# SIMG301M114KGH register map
Vendor: Silicon Labs; Series: Si; File version: B
Registers are 32-bit, read-write, reset 0x0 unless marked. A register's access mark holds for its fields unless they carry their own. Offsets are from the block's base; [hi:lo] are bit positions; {n}, {i} and the like mark numbered series; 'fields as' and 'values as' point back to an identical list.

## LFXO_NS — LFXO_NS Registers
Base 0x40820000
Same registers: LFXO_S 0x50820000
0x00 IPVERSION ro reset 0x2
  [31:0] IPVERSION — IP Version ID
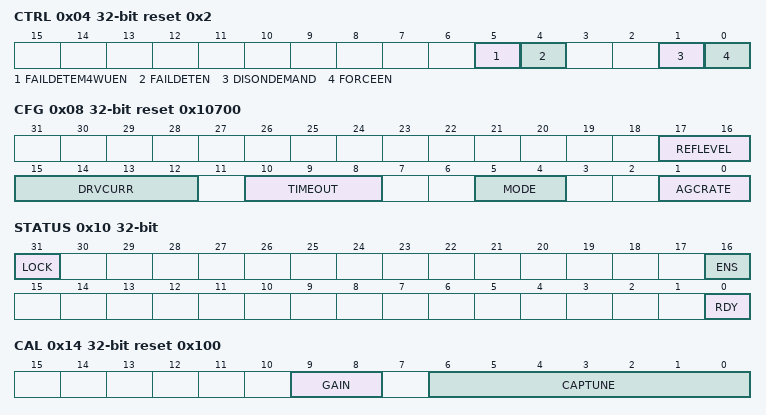
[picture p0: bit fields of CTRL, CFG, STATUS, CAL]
0x04 CTRL reset 0x2
  [5] FAILDETEM4WUEN — LFXO Failure Detection EM4WU Enable
  [4] FAILDETEN — LFXO Failure Detection Enable
  [1] DISONDEMAND — LFXO Disable On-demand requests
  [0] FORCEEN — LFXO Force Enable
0x08 CFG reset 0x10700 — Do not write to this register unless the oscillator is forced off. The oscillator is forced off if DISONDEMAND is set and FORCEEN is cleared.
  [17:16] REFLEVEL — LFXO Reference level for AGC
    0=MIN (low agc amplitude); 1=RESET (default); 3=MAX (high agc amplitude)
  [15:12] DRVCURR — LFXO Driver Current Setting
    0=AGC; {v}=FORCE_{v} (v=1..15)
  [10:8] TIMEOUT — LFXO Start-up Delay
    0=CYCLES2 (Timeout period of 2 cycles); 1=CYCLES256 (Timeout period of 256 cycles); 2=CYCLES1K (Timeout period of 1024 cycles); 3=CYCLES2K (Timeout period of 2048 cycles); 4=CYCLES4K (Timeout period of 4096 cycles); 5=CYCLES8K (Timeout period of 8192 cycles); 6=CYCLES16K (Timeout period of 16384 cycles); 7=CYCLES32K (Timeout period of 32768 cycles)
  [5:4] MODE — LFXO Mode
    0=XTAL (LFXO in Low Power mode. A 32768 Hz crystal should be connected to the LF crystal pads.); 1=XTAL_HP (LFXO in High Power mode. A 32768 Hz crystal should be connected to the LF crystal pads.); 2=BUFEXTCLK (An external sine source should be connected to LFXTAL_I pin. The input signal is internally AC coupled. Voltage should be kept above ground and below DVDD. LFXTAL_O pin is free to use as a GPIO.); 3=DIGEXTCLK (An external 32 kHz CMOS clock should be provided on LFXTAL_I. LFXTAL_O is free to be used as a general purpose GPIO.)
  [1:0] AGCRATE — LFXO AGC Refresh Rate
    0=SLOW (128k cycles); 1=MEDIUM (32k cycles); 2=FAST (8k cycles); 3=TEST (RESERVED)
0x10 STATUS ro
  [31] LOCK — LFXO Locked Status
    0=UNLOCKED (LFXO lockable registers are not locked); 1=LOCKED (LFXO lockable registers are locked)
  [16] ENS — LFXO Enable Status
  [0] RDY — LFXO Ready Status
0x14 CAL reset 0x100 — Do not write to this register unless CALBSY in SYNCBUSY register is low.
  [9:8] GAIN — LFXO Startup Gain
  [6:0] CAPTUNE — Internal Capacitance Tuning
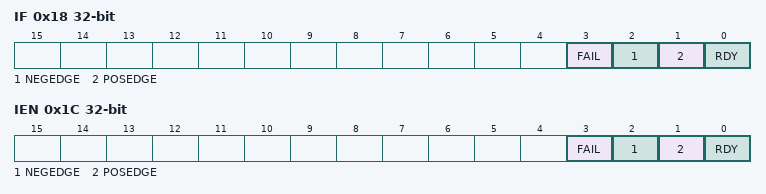
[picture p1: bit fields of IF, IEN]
0x18 IF
  [3] FAIL — LFXO Failure Interrupt Flag
  [2] NEGEDGE — Falling Edge Interrupt Flag
  [1] POSEDGE — Rising Edge Interrupt Flag
  [0] RDY — LFXO Ready Interrupt Flag
0x1C IEN
  [3] FAIL — LFXO Failure Interrupt Enable
  [2] NEGEDGE — Falling Edge Interrupt Enable
  [1] POSEDGE — Rising Edge Interrupt Enable
  [0] RDY — LFXO Ready Interrupt Enable
0x20 SYNCBUSY ro
  [0] CAL — LFXO Synchronization status
0x24 LOCK wo reset 0x1A20
  [15:0] LOCKKEY
    0x1A20=UNLOCK (Unlock LFXO lockable registers)
0x2C AGCCTRL
  [0] DISAGCCLK — LFXO AGC CLK Disable
    0=ENABLED (ENABLE AGC CLK); 1=DISABLED (DISABLE AGC CLK)

## PCNT0_NS — PCNT0_NS Registers
Base 0x40040000
Same registers: PCNT0_S 0x50040000
0x00 IPVERSION ro reset 0x1
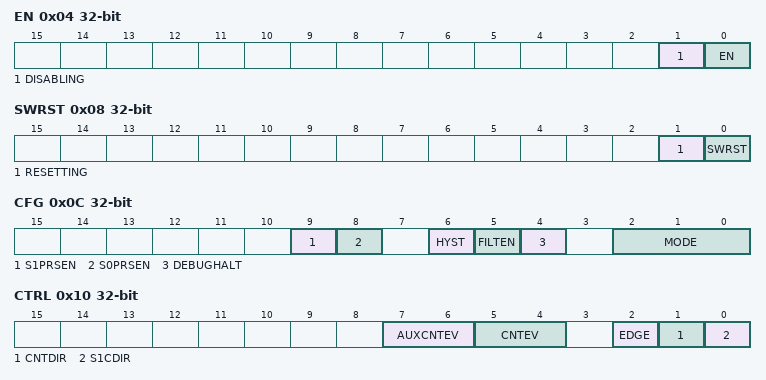
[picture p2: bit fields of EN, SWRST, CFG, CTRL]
0x04 EN
  [1] DISABLING ro — Disablement busy status
  [0] EN — PCNT Module Enable
0x08 SWRST
  [1] RESETTING ro — Software reset busy status
  [0] SWRST wo — Software reset command
0x0C CFG
  [9] S1PRSEN — S1IN PRS Enable
  [8] S0PRSEN — S0IN PRS Enable
  [6] HYST — Enable Hysteresis
  [5] FILTEN — Enable Digital Pulse Width Filter
  [4] DEBUGHALT — Debug Mode Halt Enable
    0=DISABLE (PCNT is running in debug mode.); 1=ENABLE (PCNT is frozen in debug mode.)
  [2:0] MODE — Mode Select
    0=OVSSINGLE (Single input EM23GRPACLK oversampling mode); 1=EXTCLKSINGLE (Externally clocked single input counter mode); 2=EXTCLKQUAD (Externally clocked quadrature decoder mode); 3=OVSQUAD1X (EM23GRPACLK oversampling quadrature decoder 1X mode); 4=OVSQUAD2X (EM23GRPACLK oversampling quadrature decoder 2X mode); 5=OVSQUAD4X (EM23GRPACLK oversampling quadrature decoder 4X mode)
0x10 CTRL
  [7:6] AUXCNTEV — Controls When the Aux Counter Counts
    0=BOTH (Counts up on both up-count and down-count events.); 1=UP (Counts up on up-count events.); 2=DOWN (Counts up on down-count events.)
  [5:4] CNTEV — Controls When the Counter Counts
    0=BOTH (Counts up on up-count and down on down-count events.); 1=UP (Only counts up on up-count events.); 2=DOWN (Only counts down on down-count events.)
  [2] EDGE — Edge Select
    0=POS (Positive edges on the PCNTn_S0IN inputs are counted in OVSSINGLE mode. Does not invert PCNTn_S1IN input in OVSSINGLE and EXTCLKSINGLE modes); 1=NEG (Negative edges on the PCNTn_S0IN inputs are counted in OVSSINGLE mode. Inverts the PCNTn_S1IN input in OVSSINGLE and EXTCLKSINGLE modes)
  [1] CNTDIR — Non-Quadrature Mode Counter Direction Co
    0=UP (Up counter mode.); 1=DOWN (Down counter mode.)
  [0] S1CDIR — Count Direction Determined By S1
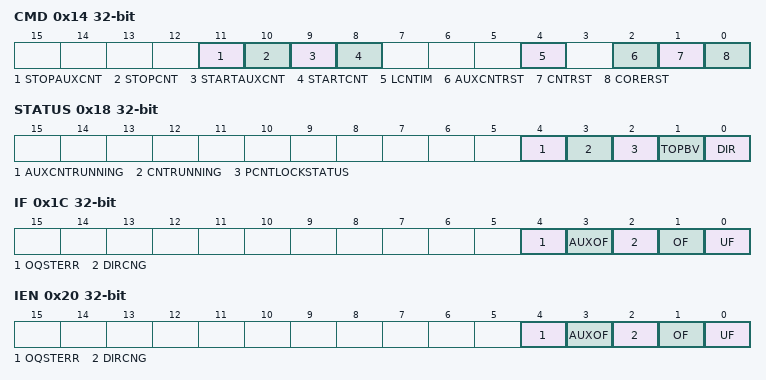
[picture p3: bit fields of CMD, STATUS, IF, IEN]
0x14 CMD wo
  [11] STOPAUXCNT — Stop Aux Counter
  [10] STOPCNT — Stop Main Counter
  [9] STARTAUXCNT — Start Aux Counter
  [8] STARTCNT — Start Main Counter
  [4] LCNTIM — Load CNT Immediately
  [2] AUXCNTRST — AUXCNT Reset
  [1] CNTRST — CNT Reset
  [0] CORERST — PCNT Clock Domain Reset
0x18 STATUS ro
  [4] AUXCNTRUNNING — Aux Counter running status
  [3] CNTRUNNING — Main Counter running status
  [2] PCNTLOCKSTATUS — Lock Status
    0=UNLOCKED (PCNT registers are unlocked); 1=LOCKED (PCNT registers are locked)
  [1] TOPBV — TOP Buffer Valid
  [0] DIR — Current Counter Direction
    0=UP (Up counter mode (clockwise in EXTCLKQUAD mode with the EDGE bit in PCNTn_CTRL set to 0).); 1=DOWN (Down counter mode.)
0x1C IF
  [4] OQSTERR — Oversampling Quad State Err Int Flag
  [3] AUXOF — Auxiliary Overflow Interrupt Read Flag
  [2] DIRCNG — Direction Change Detect Interrupt Flag
  [1] OF — Overflow Interrupt Read Flag
  [0] UF — Underflow Interrupt Read Flag
0x20 IEN
  fields as IF
0x24 CNT ro
  [15:0] CNT — Counter Value
0x28 AUXCNT ro
  [15:0] AUXCNT — Auxiliary Counter Value
0x2C TOP reset 0xFF
  [15:0] TOP — Counter Top Value
0x30 TOPB reset 0xFF
  [15:0] TOPB — Counter Top Buffer Register
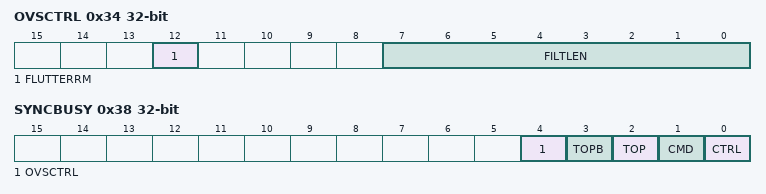
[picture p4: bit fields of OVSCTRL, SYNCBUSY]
0x34 OVSCTRL
  [12] FLUTTERRM — Flutter Remove
  [7:0] FILTLEN — Configure Filter Length for Inputs S0IN
0x38 SYNCBUSY ro
  [4] OVSCTRL — OVSCTRL Register Busy
  [3] TOPB — TOPB Register Busy
  [2] TOP — TOP Register Busy
  [1] CMD — CMD Register Busy
  [0] CTRL — CTRL Register Busy
0x3C LOCK wo
  [15:0] PCNTLOCKKEY — Configuration Lock Key
    0xA7E0=UNLOCK (Write to unock PCNT lockable registers)
